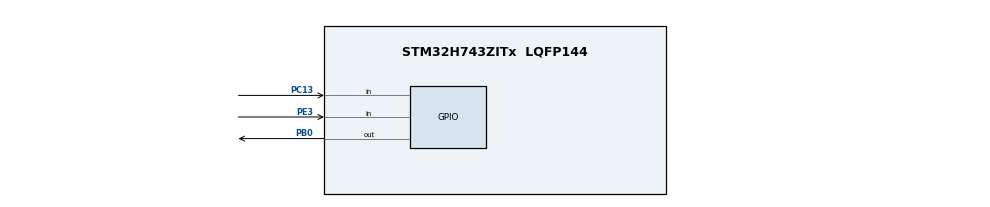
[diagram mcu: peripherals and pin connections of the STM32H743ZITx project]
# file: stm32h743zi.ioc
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Mcu.Family=STM32H7
RCC.CortexFreq_Value=64000000
PH0-OSC_IN\ (PH0).Signal=RCC_OSC_IN
PC13.Signal=GPIO_Input
PH1-OSC_OUT\ (PH1).Signal=RCC_OSC_OUT
ProjectManager.StackSize=0x400
ProjectManager.TargetToolchain=SW4STM32
RCC.HCLKFreq_Value=64000000
RCC.USBFreq_Value=129000000
PH1-OSC_OUT\ (PH1).Mode=HSE-External-Oscillator
board=custom
RCC.APB2Freq_Value=64000000
RCC.ADCFreq_Value=129000000
Mcu.Name=STM32H743ZITx
RCC.APB3Freq_Value=64000000
RCC.SYSCLKFreq_VALUE=64000000
Mcu.Package=LQFP144
ProjectManager.HeapSize=0x200
NVIC.PriorityGroup=NVIC_PRIORITYGROUP_4
RCC.APB4Freq_Value=64000000
PE3.Signal=GPIO_Input
RCC.APB1Freq_Value=64000000
PB0.Signal=GPIO_Output
PH0-OSC_IN\ (PH0).Mode=HSE-External-Oscillator

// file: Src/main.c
/* USER CODE BEGIN Header */
/**
  ******************************************************************************
  * @file           : main.c
  * @brief          : Main program body
  ******************************************************************************
  * @attention
  *
  * <h2><center>&copy; Copyright (c) 2021 STMicroelectronics.
  * All rights reserved.</center></h2>
  *
  * This software component is licensed by ST under BSD 3-Clause license,
  * the "License"; You may not use this file except in compliance with the
  * License. You may obtain a copy of the License at:
  *                        opensource.org/licenses/BSD-3-Clause
  *
  ******************************************************************************
  */
/* USER CODE END Header */

#include "main.h"

void SystemClock_Config(void);
static void MX_GPIO_Init(void);

int main(void)
{

  /* MCU Configuration--------------------------------------------------------*/

  /* Reset of all peripherals, Initializes the Flash interface and the Systick. */
  HAL_Init();

  /* Configure the system clock */
  SystemClock_Config();

  /* Initialize all configured peripherals */
  MX_GPIO_Init();
  /* USER CODE BEGIN 2 */

  /* Infinite loop */
  /* USER CODE BEGIN WHILE */
  while (1)
  {
    /* USER CODE BEGIN 3 */
	  __asm volatile ("LDR r4, =0x58020400\n" "MOV r1, #(1UL<<0)\n" "STR r1, [r4, #0x18]\n");
	  HAL_Delay(1000);
	  __asm volatile ("LDR r4, =0x58020400\n" "MOV r1, #(1UL<<16)\n" "STR r1, [r4, #0x18]\n");
	  HAL_Delay(1000);

	/* USER CODE END 3 */
  }

}

void SystemClock_Config(void)
{
  RCC_OscInitTypeDef RCC_OscInitStruct = {0};
  RCC_ClkInitTypeDef RCC_ClkInitStruct = {0};

  /** Supply configuration update enable
  */
  HAL_PWREx_ConfigSupply(PWR_LDO_SUPPLY);
  /** Configure the main internal regulator output voltage
  */
  __HAL_PWR_VOLTAGESCALING_CONFIG(PWR_REGULATOR_VOLTAGE_SCALE3);

  while(!__HAL_PWR_GET_FLAG(PWR_FLAG_VOSRDY)) {}
  /** Initializes the CPU, AHB and APB busses clocks
  */
  RCC_OscInitStruct.OscillatorType = RCC_OSCILLATORTYPE_HSI;
  RCC_OscInitStruct.HSIState = RCC_HSI_DIV1;
  RCC_OscInitStruct.HSICalibrationValue = RCC_HSICALIBRATION_DEFAULT;
  RCC_OscInitStruct.PLL.PLLState = RCC_PLL_NONE;
  if (HAL_RCC_OscConfig(&RCC_OscInitStruct) != HAL_OK)
  {
    Error_Handler();
  }
  /** Initializes the CPU, AHB and APB busses clocks
  */
  RCC_ClkInitStruct.ClockType = RCC_CLOCKTYPE_HCLK|RCC_CLOCKTYPE_SYSCLK
                              |RCC_CLOCKTYPE_PCLK1|RCC_CLOCKTYPE_PCLK2
                              |RCC_CLOCKTYPE_D3PCLK1|RCC_CLOCKTYPE_D1PCLK1;
  RCC_ClkInitStruct.SYSCLKSource = RCC_SYSCLKSOURCE_HSI;
  RCC_ClkInitStruct.SYSCLKDivider = RCC_SYSCLK_DIV1;
  RCC_ClkInitStruct.AHBCLKDivider = RCC_HCLK_DIV1;
  RCC_ClkInitStruct.APB3CLKDivider = RCC_APB3_DIV1;
  RCC_ClkInitStruct.APB1CLKDivider = RCC_APB1_DIV1;
  RCC_ClkInitStruct.APB2CLKDivider = RCC_APB2_DIV1;
  RCC_ClkInitStruct.APB4CLKDivider = RCC_APB4_DIV1;

  if (HAL_RCC_ClockConfig(&RCC_ClkInitStruct, FLASH_LATENCY_0) != HAL_OK)
  {
    Error_Handler();
  }
}

static void MX_GPIO_Init(void)
{
  GPIO_InitTypeDef GPIO_InitStruct = {0};

  /* GPIO Ports Clock Enable */
  __HAL_RCC_GPIOE_CLK_ENABLE();
  __HAL_RCC_GPIOC_CLK_ENABLE();
  __HAL_RCC_GPIOH_CLK_ENABLE();
  __HAL_RCC_GPIOB_CLK_ENABLE();

  /*Configure GPIO pin Output Level */
  HAL_GPIO_WritePin(GPIOB, GPIO_PIN_0, GPIO_PIN_RESET);

  /*Configure GPIO pin : PE3 */
  GPIO_InitStruct.Pin = GPIO_PIN_3;
  GPIO_InitStruct.Mode = GPIO_MODE_INPUT;
  GPIO_InitStruct.Pull = GPIO_NOPULL;
  HAL_GPIO_Init(GPIOE, &GPIO_InitStruct);

  /*Configure GPIO pin : PC13 */
  GPIO_InitStruct.Pin = GPIO_PIN_13;
  GPIO_InitStruct.Mode = GPIO_MODE_INPUT;
  GPIO_InitStruct.Pull = GPIO_NOPULL;
  HAL_GPIO_Init(GPIOC, &GPIO_InitStruct);

  /*Configure GPIO pin : PB0 */
  GPIO_InitStruct.Pin = GPIO_PIN_0;
  GPIO_InitStruct.Mode = GPIO_MODE_OUTPUT_PP;
  GPIO_InitStruct.Pull = GPIO_NOPULL;
  GPIO_InitStruct.Speed = GPIO_SPEED_FREQ_LOW;
  HAL_GPIO_Init(GPIOB, &GPIO_InitStruct);

}

void Error_Handler(void)
{
}

/************************ (C) COPYRIGHT STMicroelectronics *****END OF FILE****/
